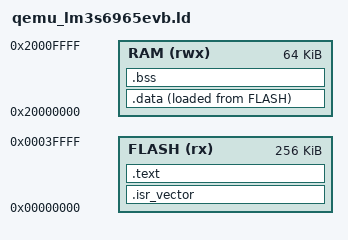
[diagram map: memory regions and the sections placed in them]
ENTRY(reset_handler)

MEMORY
{
    FLASH (rx)  : ORIGIN = 0x00000000, LENGTH = 256K
    RAM   (rwx) : ORIGIN = 0x20000000, LENGTH = 64K
}

SECTIONS
{
    .isr_vector : { KEEP(*(.isr_vector)) } > FLASH
    .text : { *(.text*) *(.rodata*) } > FLASH
    .data :
    {
        _sdata = .;
        *(.data*)
        _edata = .;
    } > RAM AT > FLASH
    _sidata = LOADADDR(.data);
    .bss (NOLOAD) :
    {
        _sbss = .;
        *(.bss*) *(COMMON)
        _ebss = .;
    } > RAM
    _stack_top = ORIGIN(RAM) + LENGTH(RAM);
    /DISCARD/ : { *(.comment*) *(.ARM.attributes*) }
}
